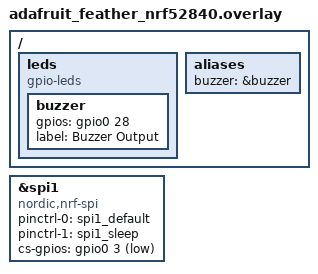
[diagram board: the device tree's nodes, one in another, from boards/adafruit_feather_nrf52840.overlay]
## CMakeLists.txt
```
cmake_minimum_required(VERSION 3.29)
find_package(Zephyr REQUIRED HINTS $ENV{ZEPHYR_BASE})

# Use the armv7em-none-none-eabi target triple for Swift
set(CMAKE_Swift_COMPILER_TARGET armv7em-none-none-eabi)
# Enable "wmo" as needed by Embedded Swift
set(CMAKE_Swift_COMPILATION_MODE wholemodule)
# FIXME: Skip checking if the compiler works
set(CMAKE_Swift_COMPILER_WORKS true)

# Create a new project called "SwiftRfid" and enable "Swift" as a supported language
project(SwiftRfid Swift)

# Set global Swift compiler flags
add_compile_options(
    # Enable Embedded Swift
    "$<$<COMPILE_LANGUAGE:Swift>:SHELL:-enable-experimental-feature Embedded>"

    # Enable function sections to enable dead code stripping on elf
    "$<$<COMPILE_LANGUAGE:Swift>:SHELL:-Xfrontend -function-sections>"

    # Enable data sections
    "$<$<COMPILE_LANGUAGE:Swift>:SHELL:-Xcc -fdata-sections>"

    # Use software floating point operations matching GCC
    "$<$<COMPILE_LANGUAGE:Swift>:SHELL:-Xcc -mfloat-abi=soft>"

    # Use compacted C enums matching GCC
    "$<$<COMPILE_LANGUAGE:Swift>:SHELL:-Xcc -fshort-enums>"

    # Disable PIC
    "$<$<COMPILE_LANGUAGE:Swift>:SHELL:-Xcc -fno-pic>"

    # Disable PIE
    "$<$<COMPILE_LANGUAGE:Swift>:SHELL:-Xcc -fno-pie>"
)

# Add TOOLCHAIN_C_FLAGS for toolchain to -Xcc flags
foreach(flag ${TOOLCHAIN_C_FLAGS})
    # Skip unknown flags
    string(FIND "${flag}" "-imacro" is_imacro)
    string(FIND "${flag}" "-mfp16-format" is_mfp16)
    if(NOT is_imacro EQUAL -1 OR NOT is_mfp16 EQUAL -1)
        continue()
    endif()

    add_compile_options("$<$<COMPILE_LANGUAGE:Swift>:SHELL:-Xcc ${flag}>")
endforeach()

# Add definitions from Zephyr to -Xcc flags
get_target_property(ZEPHYR_DEFINES zephyr_interface INTERFACE_COMPILE_DEFINITIONS)
if(ZEPHYR_DEFINES)
    foreach(flag ${ZEPHYR_DEFINES})
        # Ignore expressions like "$<SOMETHING>"
        string(FIND "${flag}" "$<" start_of_expression)
        if(NOT start_of_expression EQUAL -1)
            continue()
        endif()

        add_compile_options("$<$<COMPILE_LANGUAGE:Swift>:SHELL:-Xcc -D${flag}>")
    endforeach()
endif()

target_sources(app PRIVATE src/Stubs.c src/MFRC522.c)

# The Swift code providing "main" needs to be in an OBJECT library (instead of STATIC library) to make sure it actually gets linker.
# A STATIC library would get dropped from linking because Zephyr provides a default weak empty main definition.
add_library(app_swift OBJECT src/Main.swift src/BLE.swift src/CounterTimer.swift src/Led.swift src/MFRC522.swift)

# The code is using a String as a Dictionary key and thus require linking with libswiftUnicodeDataTables.a
# We compute the path where this file reside, taking into accout how the toolchain is referenced (Swiftly or TOOLCHAINS env variable). 
find_program(SWIFTLY "swiftly")
IF(SWIFTLY)
  execute_process(COMMAND swiftly use --print-location OUTPUT_VARIABLE toolchain_path)
  cmake_path(SET additional_lib_path NORMALIZE "${toolchain_path}/usr/lib/swift/embedded/${CMAKE_Swift_COMPILER_TARGET}")
ELSE()
  get_filename_component(compiler_bin_dir ${CMAKE_Swift_COMPILER} DIRECTORY)
  cmake_path(SET additional_lib_path NORMALIZE "${compiler_bin_dir}/../lib/swift/embedded/${CMAKE_Swift_COMPILER_TARGET}")
ENDIF()

target_link_directories(zephyr_pre0 PRIVATE "${additional_lib_path}")
target_link_libraries(zephyr_pre0
    -Wl,--no-whole-archive
    -Wl,--no-enum-size-warning
)

target_link_directories(zephyr_final PRIVATE "${additional_lib_path}")
target_link_libraries(zephyr_final
    -Wl,--no-whole-archive
    -Wl,--no-enum-size-warning
)

# Discard unused sections
zephyr_linker_sources(SECTIONS "sections.ld")

add_dependencies(app_swift syscall_list_h_target)
target_compile_options(app_swift PRIVATE
    -parse-as-library

    -Osize

    -Xfrontend -disable-stack-protector

    # FIXME: add dependency on BridgingHeader.h
    -import-bridging-header ${CMAKE_CURRENT_LIST_DIR}/src/BridgingHeader.h
)

# Copy include paths from C target to Swift target
target_include_directories(app_swift PRIVATE
    "$<TARGET_PROPERTY:app,INCLUDE_DIRECTORIES>"
)

# Link the Swift target into the primary target
target_link_libraries(app PRIVATE app_swift)
```

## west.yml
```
manifest:
  remotes:
    - name: zephyrproject-rtos
      url-base: https://github.com/zephyrproject-rtos

  projects:
    - name: zephyr
      remote: zephyrproject-rtos
      revision: v4.1.0
      import:
        name-allowlist:
          - cmsis # required by the ARM port
          - hal_nordic # required by the custom_plank board (Nordic based)
```

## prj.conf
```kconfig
CONFIG_GPIO=y
CONFIG_SPI=y
CONFIG_SPI_ASYNC=y

CONFIG_BT=y
CONFIG_BT_PERIPHERAL=y
CONFIG_BT_DEVICE_NAME="SwiftRFID"
```

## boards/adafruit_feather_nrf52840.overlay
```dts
/ {
	leds {
		compatible = "gpio-leds";
		buzzer: buzzer {
			gpios = <&gpio0 28 (GPIO_PULL_DOWN | GPIO_ACTIVE_HIGH)>;
			label = "Buzzer Output";
		};
	};

	aliases {
		// Outputs
		buzzer = &buzzer;
	};
};

&spi1 {
	compatible = "nordic,nrf-spi";
	status = "okay";
	pinctrl-0 = <&spi1_default>;
	pinctrl-1 = <&spi1_sleep>;
	pinctrl-names = "default", "sleep";
	cs-gpios = <&gpio0 3 GPIO_ACTIVE_LOW>;
};
```

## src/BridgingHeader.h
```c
#include <autoconf.h>
#include <zephyr/kernel.h>
#include <zephyr/drivers/gpio.h>

#include <zephyr/bluetooth/bluetooth.h>
#include <zephyr/bluetooth/gatt.h>
#include <zephyr/bluetooth/hci.h>

// See [struct bt_conn issue, how to include conn_internal.h - Nordic Q&A - Nordic DevZone - Nordic DevZone](https://devzone.nordicsemi.com/f/nordic-q-a/88467/struct-bt_conn-issue-how-to-include-conn_internal-h)
#include <../subsys/bluetooth/host/conn_internal.h>

#include "MFRC522.h"

#define LED0_NODE DT_ALIAS(led0)
static struct gpio_dt_spec led0 = GPIO_DT_SPEC_GET(LED0_NODE, gpios);

#define BUZZER_NODE DT_ALIAS(buzzer)
static struct gpio_dt_spec buzzer = GPIO_DT_SPEC_GET(BUZZER_NODE, gpios);
```

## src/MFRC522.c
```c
#include <stdio.h>
#include <stdint.h>
#include "MFRC522.h"

#include <zephyr/drivers/gpio.h>
#include <zephyr/drivers/spi.h>

#define PICC_TIMEOUT_5MS 0x09
#define PICC_TIMEOUT_10MS 0x13
#define PICC_TIMEOUT_15MS 0x1E

#define GPIO_CS 3

const struct device *gpio0_dev;
const struct device *spi_dev;

struct spi_config spi_cfg;
struct spi_cs_control chip;

struct spi_buf tx_buf;
struct spi_buf rx_buf;

void SPI_Init(void)
{
    spi_dev = DEVICE_DT_GET(DT_NODELABEL(spi1));
    if (!spi_dev)
    {
        printk("Failed to get SPI device\n");
        return;
    }

    gpio0_dev = DEVICE_DT_GET(DT_NODELABEL(gpio0)); // GPIO cihazını tanımla

    if (!gpio0_dev)
    {
        printk("Failed to get GPIO device\n");
        return;
    }

    // SPI yapılandırması
    spi_cfg.frequency = 4000000;
    spi_cfg.operation = SPI_WORD_SET(8) | SPI_TRANSFER_MSB | SPI_OP_MODE_GET(0);
    spi_cfg.slave = 0;

    // CS pini için yapılandırma
    chip.gpio.port = gpio0_dev;
    chip.gpio.pin = GPIO_CS;
    chip.gpio.dt_flags = GPIO_ACTIVE_LOW;
    chip.delay = 2;

    // SPI yapılandırmasına CS pinini ekle
    spi_cfg.cs = chip;

    printk("\r\nSPI device is initialized and ready.\n");
}

uint8_t TM_MFRC522_RdReg(uint8_t ucAddress)
{
    uint8_t command = ((ucAddress << 1) & 0x7E) | 0x80; // MFRC522 adresi ile okuma komutunu oluştur
    uint8_t tx_data[2] = {command, 0x00};               // Okunan veriyi alacak buffer
    uint8_t rx_data[2] = {0};                           // Okunan veriyi alacak buffer

    tx_buf.buf = tx_data;
    tx_buf.len = 2;

    rx_buf.buf = rx_data;
    rx_buf.len = 2;

    struct spi_buf_set tx = {
        .buffers = &tx_buf,
        .count = 1};

    struct spi_buf_set rx = {
        .buffers = &rx_buf,
        .count = 1};

    if (spi_transceive(spi_dev, &spi_cfg, &tx, &rx) != 0)
    {
        printk("\r\nError reading MFRC522 register\r\n");
        return 0; // Hata durumunda 0 dön
    }

    return rx_data[1]; // Okunan veriyi dön
}

void TM_MFRC522_WrReg(uint8_t ucAddress, uint8_t ucValue)
{
    uint8_t command = (ucAddress << 1) & 0x7E; // MFRC522 adresi ile yazma komutunu oluştur

    struct spi_buf_set tx_bufs;
    struct spi_buf txb[2];

    txb[0].buf = &command;
    txb[0].len = 1;
    txb[1].buf = &ucValue;
    txb[1].len = 1;

    tx_bufs.buffers = txb;
    tx_bufs.count = 2;

    int ret = spi_write(spi_dev, &spi_cfg, &tx_bufs);
    if (ret != 0)
    {
        printk("\r\nSPI transfer failed with error: %d\r\n", ret);
        // Hata durumunda gerekli işlemler yapılabilir
    }
    else
    {
        // SPI iletişimi başarıyla gerçekleştirildi
    }
}

void TM_MFRC522_Init(void)
{

    TM_MFRC522_Reset();

    TM_MFRC522_WrReg(MFRC522_REG_T_MODE, 0x8D);
    TM_MFRC522_WrReg(MFRC522_REG_T_PRESCALER, 0x3E);

    TM_MFRC522_WrReg(MFRC522_REG_T_RELOAD_L, 0x09);
    TM_MFRC522_WrReg(MFRC522_REG_T_RELOAD_H, 0);

    TM_MFRC522_WrReg(MFRC522_REG_TX_AUTO, 0x40);
    TM_MFRC522_WrReg(MFRC522_REG_MODE, 0x3D);

    TM_MFRC522_WrReg(MFRC522_REG_RF_CFG, 0x70);

    TM_MFRC522_SetBitMask(MFRC522_REG_DIV1_EN, 0x80);

    TM_MFRC522_AntennaOn();
}

/* A function to initialize SPI Instance */

void TM_MFRC522_SetBitMask(uint8_t reg, uint8_t mask)
{
    TM_MFRC522_WrReg(reg, TM_MFRC522_RdReg(reg) | mask);
}

void TM_MFRC522_ClearBitMask(uint8_t reg, uint8_t mask)
{
    TM_MFRC522_WrReg(reg, TM_MFRC522_RdReg(reg) & (~mask));
}

void TM_MFRC522_AntennaOn(void)
{
    uint8_t temp;

    temp = TM_MFRC522_RdReg(MFRC522_REG_TX_CONTROL);
    if (!(temp & 0x03))
        TM_MFRC522_SetBitMask(MFRC522_REG_TX_CONTROL, 0x03);
}

void TM_MFRC522_AntennaOff(void)
{
    TM_MFRC522_ClearBitMask(MFRC522_REG_TX_CONTROL, 0x03);
}

void TM_MFRC522_Reset(void)
{
    uint8_t temp;

    TM_MFRC522_WrReg(MFRC522_REG_COMMAND, PCD_RESETPHASE);

    do
    {
        temp = TM_MFRC522_RdReg(MFRC522_REG_COMMAND);
        temp &= 0x10;
    } while (temp);
}

uint8_t MFRC522_ToCard(uint8_t command, uint8_t *sendData, uint8_t sendLen, uint8_t *backData, unsigned *backLen)
{
    uint8_t _status = MI_ERR;
    uint8_t irqEn = 0x00;
    uint8_t waitIRq = 0x00;
    uint8_t lastBits;
    uint8_t n;
    unsigned i;

    switch (command)
    {
    case PCD_AUTHENT:
    {
        irqEn = 0x12;
        waitIRq = 0x10;
        break;
    }
    case PCD_TRANSCEIVE:
    {
        irqEn = 0x77;
        waitIRq = 0x30;
        break;
    }
    default:
        break;
    }

    TM_MFRC522_WrReg(MFRC522_REG_COMM_IE_N, irqEn | 0x80);
    TM_MFRC522_ClearBitMask(MFRC522_REG_COMM_IRQ, 0x80);
    TM_MFRC522_SetBitMask(MFRC522_REG_FIFO_LEVEL, 0x80);
    TM_MFRC522_WrReg(MFRC522_REG_COMMAND, PCD_IDLE);

    for (i = 0; i < sendLen; i++)
    {
        TM_MFRC522_WrReg(MFRC522_REG_FIFO_DATA, sendData[i]);
    }

    TM_MFRC522_WrReg(MFRC522_REG_COMMAND, command);

    if (command == PCD_TRANSCEIVE)
    {
        TM_MFRC522_SetBitMask(MFRC522_REG_BIT_FRAMING, 0x80);
    }

    i = 0xFFFF;
    do
    {

        n = TM_MFRC522_RdReg(MFRC522_REG_COMM_IRQ);
        i--;
    } while (i && !(n & 0x01) && !(n & waitIRq));

    TM_MFRC522_ClearBitMask(MFRC522_REG_BIT_FRAMING, 0x80);

    if (i != 0)
    {
        if (!(TM_MFRC522_RdReg(MFRC522_REG_ERROR) & 0x1B))
        {
            _status = MI_OK;
            if (n & irqEn & 0x01)
            {
                _status = MI_NOTAGERR;
            }

            if (command == PCD_TRANSCEIVE)
            {
                n = TM_MFRC522_RdReg(MFRC522_REG_FIFO_LEVEL);
                lastBits = TM_MFRC522_RdReg(MFRC522_REG_CONTROL) & 0x07;
                if (lastBits)
                {
                    *backLen = (n - 1) * 8 + lastBits;
                }
                else
                {
                    *backLen = n * 8;
                }

                if (n == 0)
                {
                    n = 1;
                }

                if (n > 16)
                {
                    n = 16;
                }

                for (i = 0; i < n; i++)
                {
                    backData[i] = TM_MFRC522_RdReg(MFRC522_REG_FIFO_DATA);
                }

                backData[i] = 0;
            }
        }
        else
        {
            _status = MI_ERR;
        }
    }

    return _status;
}

uint8_t MFRC522_Request(uint8_t reqMode, uint8_t *TagType)
{
    uint8_t _status;
    unsigned backBits;

    TM_MFRC522_WrReg(MFRC522_REG_BIT_FRAMING, 0x07);

    TagType[0] = reqMode;
    _status = MFRC522_ToCard(PCD_TRANSCEIVE, TagType, 1, TagType, &backBits);

    if ((_status != MI_OK) || (backBits != 0x10))
    {
        _status = MI_ERR;
    }

    return _status;
}

uint8_t MFRC522_isCard(uint8_t *TagType)
{
    if (MFRC522_Request(PICC_REQA, TagType) == MI_OK)

        return 1;
    else
        return 0;
}

TM_MFRC522_STS_T TM_MFRC522_Anticoll(uint8_t *serNum)
{
    TM_MFRC522_STS_T status;
    uint8_t i;
    uint8_t serNumCheck = 0;
    uint16_t unLen;

    TM_MFRC522_ClearBitMask(MFRC522_REG_STATUS2, 0x08);
    TM_MFRC522_WrReg(MFRC522_REG_BIT_FRAMING, 0x00); // TxLastBists = BitFramingReg[2..0]
    TM_MFRC522_SetBitMask(MFRC522_REG_COLL, 0x80);

    /* ANTICOLLISION command with NVB does not specify 40 valid bits (NVB not to 0x70) */
    /* Note: "NVB=0x20" defines that the PCD will transmit no part of UID CLn, and it forces all
             PICCs in the field to respond with their complete UID CLn. */
    serNum[0] = PICC_ANTICOLL;
    serNum[1] = 0x20; // NVB
    status = TM_MFRC522_ToCard(PCD_TRANSCEIVE, serNum, 2, serNum, &unLen);

    if (status == MI_OK)
    {
        /* Check card serial number */
        for (i = 0; i < 4; i++)
        {
            serNumCheck ^= serNum[i];
        }

        /* BCC: UID CLn checkbyte and is calculated
           as exclusive-or over the 4 previous bytes */
        if (serNumCheck != serNum[i])
        {
            status = MI_ERR;
        }
    }
    TM_MFRC522_SetBitMask(MFRC522_REG_COLL, 0x80);

    return status;
}

TM_MFRC522_STS_T TM_MFRC522_ToCard(uint8_t command, uint8_t *sendData, uint8_t sendLen, uint8_t *backData, uint16_t *backLen)
{
    TM_MFRC522_STS_T status = MI_ERR;
    uint8_t irqEn = 0x00;
    uint8_t waitFor = 0x00;
    uint8_t lastBits;
    uint8_t regValue;
    uint16_t i;

    switch (command)
    {
    case PCD_AUTHENT:
        irqEn = 0x13;
        waitFor = 0x10;
        //    irqEn = 0x12; (original setting)
        break;
    case PCD_TRANSCEIVE:
        /* TxIRq(b6), RxIRq(b5), IdleIRq(b4),
           HiAlerIRq(b3), LoAlertIRq(b2), ErrIRq(b1), TimerIRq(b0) */
        /* wait response from PICC or 5 ms timeout */
        irqEn = 0x21;
        waitFor = 0x30;
        break;
    default:
        break;
    }
    /* IRQ pin is inverted with respect to the Status1Reg register’s IRq bit */
    TM_MFRC522_WrReg(MFRC522_REG_COMM_IE_N, irqEn | 0x80);

    /* Clear marked bits in ComIrqReg register */
    TM_MFRC522_ClearBitMask(MFRC522_REG_COMM_IRQ, 0x80);

    TM_MFRC522_WrReg(MFRC522_REG_COMMAND, PCD_IDLE);

    /* Flush FIFO contents */
    TM_MFRC522_SetBitMask(MFRC522_REG_FIFO_LEVEL, 0x80);

    /* Cancel current comand execution */
    TM_MFRC522_WrReg(MFRC522_REG_COMMAND, PCD_IDLE);

    /* Write data to FIFO */
    for (i = 0; i < sendLen; i++)
    {
        TM_MFRC522_WrReg(MFRC522_REG_FIFO_DATA, sendData[i]);
    }

    /* Execute PCD_TRANSCEIVE command */
    TM_MFRC522_WrReg(MFRC522_REG_COMMAND, command);

    if (command == PCD_TRANSCEIVE)
    {
        /* Start frame transmission */
        TM_MFRC522_SetBitMask(MFRC522_REG_BIT_FRAMING, 0x80);
    }

    i = 1000;
    /* Wait response from PICC or internal timer 5 ms timeout happened */
    do
    {

        regValue = TM_MFRC522_RdReg(MFRC522_REG_COMM_IRQ);
        i--;
    } while ((i != 0) && !(regValue & 0x01) && !(regValue & waitFor));

    /* Set StartSend=0 */
    TM_MFRC522_ClearBitMask(MFRC522_REG_BIT_FRAMING, 0x80);

    /* Check if internal timer timeout */
    if (!(regValue & 0x01))
    {
        if (i != 0)
        {
            if (!(TM_MFRC522_RdReg(MFRC522_REG_ERROR) & 0x1B))
            {
                status = MI_OK;

                if (command == PCD_TRANSCEIVE)
                {
                    /* Check the number of bytes stored in FIFO */
                    regValue = TM_MFRC522_RdReg(MFRC522_REG_FIFO_LEVEL);

                    /* Check valid bit number of last byte */
                    lastBits = TM_MFRC522_RdReg(MFRC522_REG_CONTROL) & 0x07;
                    if (lastBits)
                        *backLen = (regValue - 1) * 8 + lastBits;
                    else
                        *backLen = regValue * 8;

                    if (regValue == 0)
                        regValue = 1;
                    if (regValue > MFRC522_MAX_LEN)
                        regValue = MFRC522_MAX_LEN;

                    /* Read received data in FIFO */
                    for (i = 0; i < regValue; i++)
                        backData[i] = TM_MFRC522_RdReg(MFRC522_REG_FIFO_DATA);
                }
            }
            else
            {
                status = MI_ERR;
            }
        }
    }
    TM_MFRC522_SetBitMask(MFRC522_REG_CONTROL, 0x80);
    TM_MFRC522_WrReg(MFRC522_REG_COMMAND, PCD_IDLE);
    return status;
}

void TM_MFRC522_CalculateCRC(uint8_t *pIndata, uint8_t len, uint8_t *pOutData)
{
    uint8_t i, n;

    TM_MFRC522_ClearBitMask(MFRC522_REG_DIV_IRQ, 0x04);

    TM_MFRC522_SetBitMask(MFRC522_REG_FIFO_LEVEL, 0x80);

    for (i = 0; i < len; i++)
    {
        TM_MFRC522_WrReg(MFRC522_REG_FIFO_DATA, *(pIndata + i));
    }
    TM_MFRC522_WrReg(MFRC522_REG_COMMAND, PCD_CALCCRC);

    i = 0xFF;
    do
    {
        n = TM_MFRC522_RdReg(MFRC522_REG_DIV_IRQ);
        i--;
    } while ((i != 0) && !(n & 0x04));

    pOutData[0] = TM_MFRC522_RdReg(MFRC522_REG_CRC_RESULT_L);
    pOutData[1] = TM_MFRC522_RdReg(MFRC522_REG_CRC_RESULT_M);
}

void TM_MFRC522_Halt(void)
{

    unsigned unLen;
    uint8_t buff[4];

    buff[0] = PICC_HALT;
    buff[1] = 0;
    TM_MFRC522_CalculateCRC(buff, 2, &buff[2]);

    if (MFRC522_ToCard(PCD_TRANSCEIVE, buff, 4, buff, &unLen) != MI_NOTAGERR)
    {
        printf("Halt command error. \n");
    }
}

uint8_t TM_MFRC522_Check(uint8_t *id)
{
    uint8_t status;
    uint8_t cardtype[3];

    status = MFRC522_Request(PICC_REQA, cardtype);
    if (status == MI_OK)
        status = TM_MFRC522_Anticoll(id);
    else
        status = MI_ERR;

    return status;
}
```

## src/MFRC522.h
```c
#ifndef MFRC522_H
#define MFRC522_H

/* MFRC522 status */
typedef enum
{
    MI_OK = 0,
    MI_NOTAGERR,
    MI_ERR
} TM_MFRC522_STS_T;

/* MFRC522 commands */
#define PCD_IDLE 0x00       // No action; Cancel the current command
#define PCD_AUTHENT 0x0E    // Authentication Key
#define PCD_RECEIVE 0x08    // Receive Data
#define PCD_TRANSMIT 0x04   // Transmit data
#define PCD_TRANSCEIVE 0x0C // Transmit and receive data,
#define PCD_RESETPHASE 0x0F // Reset
#define PCD_CALCCRC 0x03    // CRC Calculate

/* Mifare One card command word */
#define PICC_REQA 0x26      // find the antenna area does not enter hibernation
#define PICC_WAKEUP 0x52    // find all the cards antenna area
#define PICC_ANTICOLL 0x93  // anti-collision
#define PICC_SElECTTAG 0x93 // election card
#define PICC_AUTHENT1A 0x60 // authentication key A
#define PICC_AUTHENT1B 0x61 // authentication key B
#define PICC_READ 0x30      // Read Block
#define PICC_WRITE 0xA0     // write block
#define PICC_DECREMENT 0xC0 // debit
#define PICC_INCREMENT 0xC1 // recharge
#define PICC_RESTORE 0xC2   // transfer block data to the buffer
#define PICC_TRANSFER 0xB0  // save the data in the buffer
#define PICC_HALT 0x50      // Sleep

/* MFRC522 Registers */
/* Page 0: Command and Status */
#define MFRC522_REG_RESERVED00 0x00
#define MFRC522_REG_COMMAND 0x01
#define MFRC522_REG_COMM_IE_N 0x02
#define MFRC522_REG_DIV1_EN 0x03
#define MFRC522_REG_COMM_IRQ 0x04
#define MFRC522_REG_DIV_IRQ 0x05
#define MFRC522_REG_ERROR 0x06
#define MFRC522_REG_STATUS1 0x07
#define MFRC522_REG_STATUS2 0x08
#define MFRC522_REG_FIFO_DATA 0x09
#define MFRC522_REG_FIFO_LEVEL 0x0A
#define MFRC522_REG_WATER_LEVEL 0x0B
#define MFRC522_REG_CONTROL 0x0C
#define MFRC522_REG_BIT_FRAMING 0x0D
#define MFRC522_REG_COLL 0x0E
#define MFRC522_REG_RESERVED01 0x0F

/* Page 1: Command */
#define MFRC522_REG_RESERVED10 0x10
#define MFRC522_REG_MODE 0x11
#define MFRC522_REG_TX_MODE 0x12
#define MFRC522_REG_RX_MODE 0x13
#define MFRC522_REG_TX_CONTROL 0x14
#define MFRC522_REG_TX_AUTO 0x15
#define MFRC522_REG_TX_SELL 0x16
#define MFRC522_REG_RX_SELL 0x17
#define MFRC522_REG_RX_THRESHOLD 0x18
#define MFRC522_REG_DEMOD 0x19
#define MFRC522_REG_RESERVED11 0x1A
#define MFRC522_REG_RESERVED12 0x1B
#define MFRC522_REG_MIFARE 0x1C
#define MFRC522_REG_RESERVED13 0x1D
#define MFRC522_REG_RESERVED14 0x1E
#define MFRC522_REG_SERIALSPEED 0x1F

/* Page 2: Configuration */
#define MFRC522_REG_RESERVED20 0x20
#define MFRC522_REG_CRC_RESULT_M 0x21
#define MFRC522_REG_CRC_RESULT_L 0x22
#define MFRC522_REG_RESERVED21 0x23
#define MFRC522_REG_MOD_WIDTH 0x24
#define MFRC522_REG_RESERVED22 0x25
#define MFRC522_REG_RF_CFG 0x26
#define MFRC522_REG_GS_N 0x27
#define MFRC522_REG_CWGS_PREG 0x28
#define MFRC522_REG__MODGS_PREG 0x29
#define MFRC522_REG_T_MODE 0x2A
#define MFRC522_REG_T_PRESCALER 0x2B
#define MFRC522_REG_T_RELOAD_H 0x2C
#define MFRC522_REG_T_RELOAD_L 0x2D
#define MFRC522_REG_T_COUNTER_VALUE_H 0x2E
#define MFRC522_REG_T_COUNTER_VALUE_L 0x2F

/* Page 3:TestRegister */
#define MFRC522_REG_RESERVED30 0x30
#define MFRC522_REG_TEST_SEL1 0x31
#define MFRC522_REG_TEST_SEL2 0x32
#define MFRC522_REG_TEST_PIN_EN 0x33
#define MFRC522_REG_TEST_PIN_VALUE 0x34
#define MFRC522_REG_TEST_BUS 0x35
#define MFRC522_REG_AUTO_TEST 0x36
#define MFRC522_REG_VERSION 0x37
#define MFRC522_REG_ANALOG_TEST 0x38
#define MFRC522_REG_TEST_ADC1 0x39
#define MFRC522_REG_TEST_ADC2 0x3A
#define MFRC522_REG_TEST_ADC0 0x3B
#define MFRC522_REG_RESERVED31 0x3C
#define MFRC522_REG_RESERVED32 0x3D
#define MFRC522_REG_RESERVED33 0x3E
#define MFRC522_REG_RESERVED34 0x3F

#define MFRC522_DUMMY 0x00
#define MFRC522_MAX_LEN 16

/*---------------------------------------------------------------------------------------------------------*/
/* Function declaration                                                                                    */
/*---------------------------------------------------------------------------------------------------------*/
void MFRC522_Halt();

void SPI_Init(void);
void TM_MFRC522_Init(void);
uint8_t TM_MFRC522_RdReg(uint8_t ucAddress);
void TM_MFRC522_WrReg(uint8_t ucAddress, uint8_t ucValue);
void TM_MFRC522_SetBitMask(uint8_t reg, uint8_t mask);
void TM_MFRC522_ClearBitMask(uint8_t reg, uint8_t mask);
void TM_MFRC522_AntennaOn(void);
void TM_MFRC522_AntennaOff(void);
void TM_MFRC522_Reset(void);
uint8_t MFRC522_ToCard(uint8_t command, uint8_t *sendData, uint8_t sendLen, uint8_t *backData, unsigned *backLen);
uint8_t MFRC522_isCard(uint8_t *TagType);
TM_MFRC522_STS_T TM_MFRC522_ToCard(uint8_t command, uint8_t *sendData, uint8_t sendLen, uint8_t *backData, uint16_t *backLen);
TM_MFRC522_STS_T TM_MFRC522_Anticoll(uint8_t *serNum);
void TM_MFRC522_CalculateCRC(uint8_t *pIndata, uint8_t len, uint8_t *pOutData);
void TM_MFRC522_Halt(void);
uint8_t TM_MFRC522_Check(uint8_t *id);
uint8_t MFRC522_Request(uint8_t reqMode, uint8_t *TagType);
#endif
```
